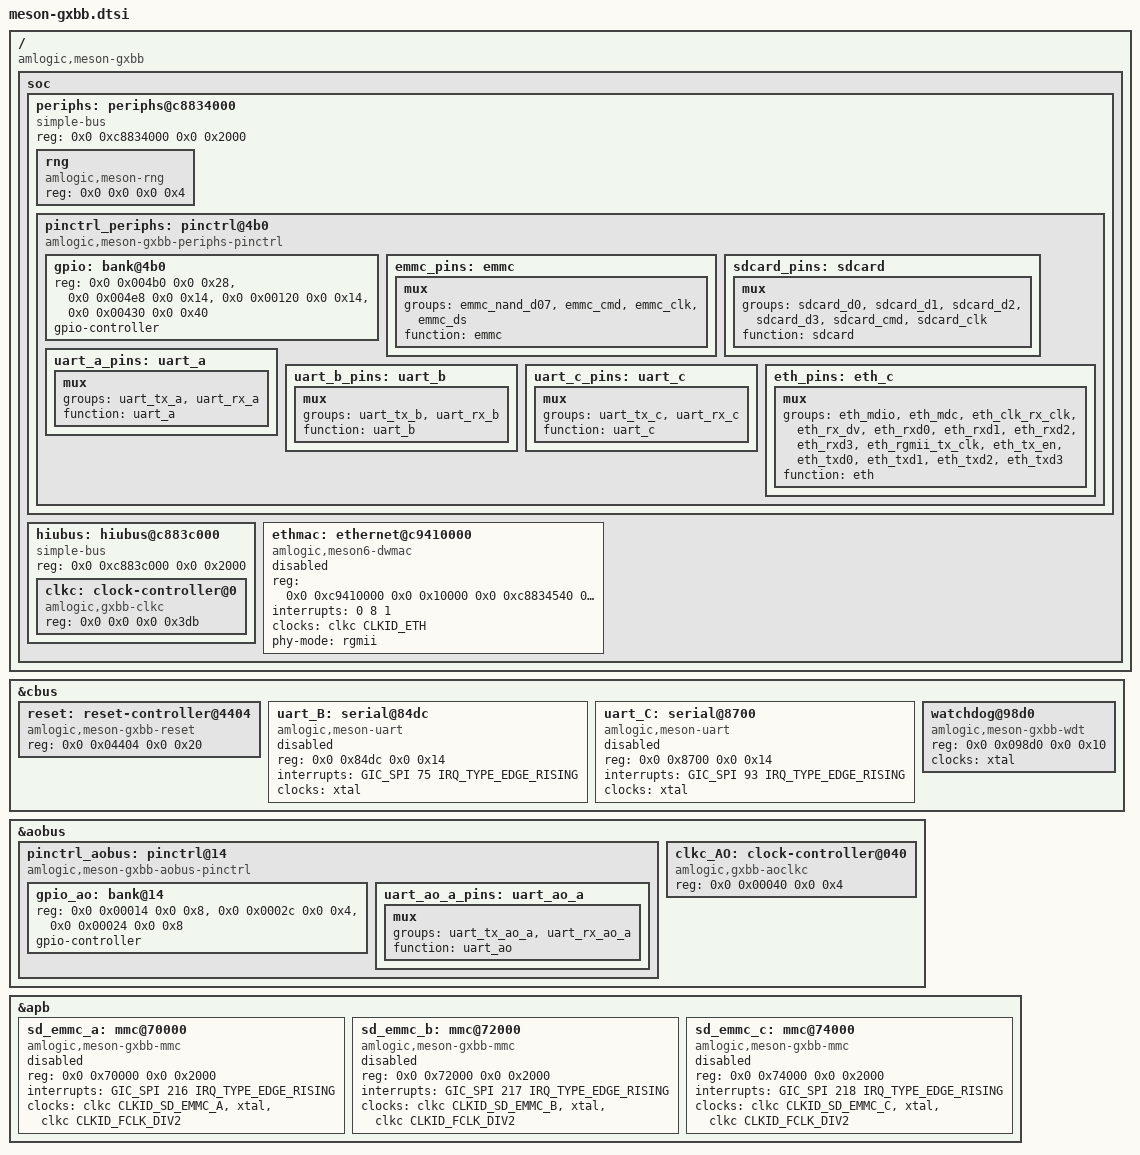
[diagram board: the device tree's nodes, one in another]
/*
 * Copyright (c) 2016 Andreas Färber
 *
 * This file is dual-licensed: you can use it either under the terms
 * of the GPL or the X11 license, at your option. Note that this dual
 * licensing only applies to this file, and not this project as a
 * whole.
 *
 *  a) This library is free software; you can redistribute it and/or
 *     modify it under the terms of the GNU General Public License as
 *     published by the Free Software Foundation; either version 2 of the
 *     License, or (at your option) any later version.
 *
 *     This library is distributed in the hope that it will be useful,
 *     but WITHOUT ANY WARRANTY; without even the implied warranty of
 *     MERCHANTABILITY or FITNESS FOR A PARTICULAR PURPOSE.  See the
 *     GNU General Public License for more details.
 *
 * Or, alternatively,
 *
 *  b) Permission is hereby granted, free of charge, to any person
 *     obtaining a copy of this software and associated documentation
 *     files (the "Software"), to deal in the Software without
 *     restriction, including without limitation the rights to use,
 *     copy, modify, merge, publish, distribute, sublicense, and/or
 *     sell copies of the Software, and to permit persons to whom the
 *     Software is furnished to do so, subject to the following
 *     conditions:
 *
 *     The above copyright notice and this permission notice shall be
 *     included in all copies or substantial portions of the Software.
 *
 *     THE SOFTWARE IS PROVIDED "AS IS", WITHOUT WARRANTY OF ANY KIND,
 *     EXPRESS OR IMPLIED, INCLUDING BUT NOT LIMITED TO THE WARRANTIES
 *     OF MERCHANTABILITY, FITNESS FOR A PARTICULAR PURPOSE AND
 *     NONINFRINGEMENT. IN NO EVENT SHALL THE AUTHORS OR COPYRIGHT
 *     HOLDERS BE LIABLE FOR ANY CLAIM, DAMAGES OR OTHER LIABILITY,
 *     WHETHER IN AN ACTION OF CONTRACT, TORT OR OTHERWISE, ARISING
 *     FROM, OUT OF OR IN CONNECTION WITH THE SOFTWARE OR THE USE OR
 *     OTHER DEALINGS IN THE SOFTWARE.
 */

#include "meson-gx.dtsi"
#include <dt-bindings/gpio/meson-gxbb-gpio.h>
#include <dt-bindings/reset/amlogic,meson-gxbb-reset.h>
#include <dt-bindings/clock/gxbb-clkc.h>
#include <dt-bindings/clock/gxbb-aoclkc.h>
#include <dt-bindings/reset/gxbb-aoclkc.h>

/ {
	compatible = "amlogic,meson-gxbb";

	soc {
		periphs: periphs@c8834000 {
			compatible = "simple-bus";
			reg = <0x0 0xc8834000 0x0 0x2000>;
			#address-cells = <2>;
			#size-cells = <2>;
			ranges = <0x0 0x0 0x0 0xc8834000 0x0 0x2000>;

			rng {
				compatible = "amlogic,meson-rng";
				reg = <0x0 0x0 0x0 0x4>;
			};

			pinctrl_periphs: pinctrl@4b0 {
				compatible = "amlogic,meson-gxbb-periphs-pinctrl";
				#address-cells = <2>;
				#size-cells = <2>;
				ranges;

				gpio: bank@4b0 {
					reg = <0x0 0x004b0 0x0 0x28>,
					      <0x0 0x004e8 0x0 0x14>,
					      <0x0 0x00120 0x0 0x14>,
					      <0x0 0x00430 0x0 0x40>;
					reg-names = "mux", "pull", "pull-enable", "gpio";
					gpio-controller;
					#gpio-cells = <2>;
				};

				emmc_pins: emmc {
					mux {
						groups = "emmc_nand_d07",
						       "emmc_cmd",
						       "emmc_clk",
						       "emmc_ds";
						function = "emmc";
					};
				};

				sdcard_pins: sdcard {
					mux {
						groups = "sdcard_d0",
						       "sdcard_d1",
						       "sdcard_d2",
						       "sdcard_d3",
						       "sdcard_cmd",
						       "sdcard_clk";
						function = "sdcard";
					};
				};

				uart_a_pins: uart_a {
					mux {
						groups = "uart_tx_a",
						       "uart_rx_a";
						function = "uart_a";
					};
				};

				uart_b_pins: uart_b {
					mux {
						groups = "uart_tx_b",
						       "uart_rx_b";
						function = "uart_b";
					};
				};

				uart_c_pins: uart_c {
					mux {
						groups = "uart_tx_c",
						       "uart_rx_c";
						function = "uart_c";
					};
				};

				eth_pins: eth_c {
					mux {
						groups = "eth_mdio",
						       "eth_mdc",
						       "eth_clk_rx_clk",
						       "eth_rx_dv",
						       "eth_rxd0",
						       "eth_rxd1",
						       "eth_rxd2",
						       "eth_rxd3",
						       "eth_rgmii_tx_clk",
						       "eth_tx_en",
						       "eth_txd0",
						       "eth_txd1",
						       "eth_txd2",
						       "eth_txd3";
						function = "eth";
					};
				};
			};
		};

		hiubus: hiubus@c883c000 {
			compatible = "simple-bus";
			reg = <0x0 0xc883c000 0x0 0x2000>;
			#address-cells = <2>;
			#size-cells = <2>;
			ranges = <0x0 0x0 0x0 0xc883c000 0x0 0x2000>;

			clkc: clock-controller@0 {
				compatible = "amlogic,gxbb-clkc";
				#clock-cells = <1>;
				reg = <0x0 0x0 0x0 0x3db>;
			};
		};

		ethmac: ethernet@c9410000 {
			compatible = "amlogic,meson6-dwmac", "snps,dwmac";
			reg = <0x0 0xc9410000 0x0 0x10000
			       0x0 0xc8834540 0x0 0x4>;
			interrupts = <0 8 1>;
			interrupt-names = "macirq";
			clocks = <&clkc CLKID_ETH>;
			clock-names = "stmmaceth";
			phy-mode = "rgmii";
			status = "disabled";
		};
	};
};

&cbus {
	reset: reset-controller@4404 {
		compatible = "amlogic,meson-gxbb-reset";
		reg = <0x0 0x04404 0x0 0x20>;
		#reset-cells = <1>;
	};

	uart_B: serial@84dc {
		compatible = "amlogic,meson-uart";
		reg = <0x0 0x84dc 0x0 0x14>;
		interrupts = <GIC_SPI 75 IRQ_TYPE_EDGE_RISING>;
		clocks = <&xtal>;
		status = "disabled";
	};

	uart_C: serial@8700 {
		compatible = "amlogic,meson-uart";
		reg = <0x0 0x8700 0x0 0x14>;
		interrupts = <GIC_SPI 93 IRQ_TYPE_EDGE_RISING>;
		clocks = <&xtal>;
		status = "disabled";
	};

	watchdog@98d0 {
		compatible = "amlogic,meson-gxbb-wdt";
		reg = <0x0 0x098d0 0x0 0x10>;
		clocks = <&xtal>;
	};
};

&aobus {
	pinctrl_aobus: pinctrl@14 {
		compatible = "amlogic,meson-gxbb-aobus-pinctrl";
		#address-cells = <2>;
		#size-cells = <2>;
		ranges;

		gpio_ao: bank@14 {
			reg = <0x0 0x00014 0x0 0x8>,
			      <0x0 0x0002c 0x0 0x4>,
			      <0x0 0x00024 0x0 0x8>;
			reg-names = "mux", "pull", "gpio";
			gpio-controller;
			#gpio-cells = <2>;
		};

		uart_ao_a_pins: uart_ao_a {
			mux {
				groups = "uart_tx_ao_a", "uart_rx_ao_a";
				function = "uart_ao";
			};
		};
	};

	clkc_AO: clock-controller@040 {
		compatible = "amlogic,gxbb-aoclkc";
		reg = <0x0 0x00040 0x0 0x4>;
		#clock-cells = <1>;
		#reset-cells = <1>;
	};
};

&apb {
	sd_emmc_a: mmc@70000 {
		compatible = "amlogic,meson-gxbb-mmc";
		reg = <0x0 0x70000 0x0 0x2000>;
		interrupts = <GIC_SPI 216 IRQ_TYPE_EDGE_RISING>;
		clocks = <&clkc CLKID_SD_EMMC_A>,
			 <&xtal>,
			 <&clkc CLKID_FCLK_DIV2>;
		clock-names = "core", "clkin0", "clkin1";
		status = "disabled";
	};

	sd_emmc_b: mmc@72000 {
		compatible = "amlogic,meson-gxbb-mmc";
		reg = <0x0 0x72000 0x0 0x2000>;
		interrupts = <GIC_SPI 217 IRQ_TYPE_EDGE_RISING>;
		clocks = <&clkc CLKID_SD_EMMC_B>,
			 <&xtal>,
			 <&clkc CLKID_FCLK_DIV2>;
		clock-names = "core", "clkin0", "clkin1";
		status = "disabled";
	};

	sd_emmc_c: mmc@74000 {
		compatible = "amlogic,meson-gxbb-mmc";
		reg = <0x0 0x74000 0x0 0x2000>;
		interrupts = <GIC_SPI 218 IRQ_TYPE_EDGE_RISING>;
		clocks = <&clkc CLKID_SD_EMMC_C>,
			 <&xtal>,
			 <&clkc CLKID_FCLK_DIV2>;
		clock-names = "core", "clkin0", "clkin1";
		status = "disabled";
	};
};

